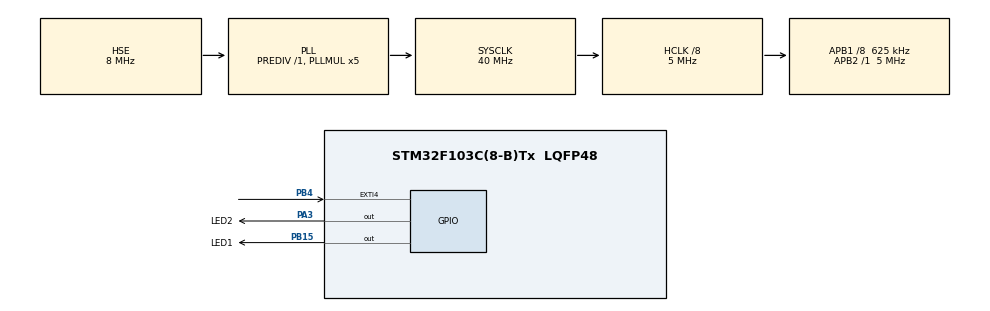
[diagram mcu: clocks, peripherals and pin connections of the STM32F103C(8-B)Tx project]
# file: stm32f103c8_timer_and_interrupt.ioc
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Mcu.Family=STM32F1
Mcu.Name=STM32F103C(8-B)Tx
Mcu.Package=LQFP48
NVIC.EXTI4_IRQn=true\:1\:0\:true\:false\:true\:true\:true\:true
NVIC.PriorityGroup=NVIC_PRIORITYGROUP_2
NVIC.TIM1_UP_IRQn=true\:2\:0\:true\:false\:true\:true\:true\:true
PA3.GPIO_Label=LED2
PA3.Signal=GPIO_Output
PB15.GPIO_Label=LED1
PB15.Signal=GPIO_Output
PB4.GPIO_ModeDefaultEXTI=GPIO_MODE_IT_FALLING
PB4.GPIO_PuPd=GPIO_PULLUP
PB4.Signal=GPXTI4
PD0-OSC_IN.Mode=HSE-External-Oscillator
PD0-OSC_IN.Signal=RCC_OSC_IN
PD1-OSC_OUT.Mode=HSE-External-Oscillator
PD1-OSC_OUT.Signal=RCC_OSC_OUT
ProjectManager.HeapSize=0x200
ProjectManager.StackSize=0x400
ProjectManager.TargetToolchain=STM32CubeIDE
RCC.AHBCLKDivider=RCC_SYSCLK_DIV8
RCC.AHBFreq_Value=5000000
RCC.APB1CLKDivider=RCC_HCLK_DIV8
RCC.APB1Freq_Value=625000
RCC.APB1TimFreq_Value=1250000
RCC.APB2Freq_Value=5000000
RCC.APB2TimFreq_Value=5000000
RCC.HCLKFreq_Value=5000000
RCC.PLLMUL=RCC_PLL_MUL5
RCC.PLLSourceVirtual=RCC_PLLSOURCE_HSE
RCC.SYSCLKFreq_VALUE=40000000
RCC.SYSCLKSource=RCC_SYSCLKSOURCE_PLLCLK
RCC.TimSys_Div=SYSTICK_CLKSOURCE_HCLK_DIV8
RCC.USBFreq_Value=40000000
TIM1.Period=5000
TIM1.RepetitionCounter=0
VP_SYS_VS_ND.Mode=No_Debug
VP_TIM1_VS_ClockSourceINT.Mode=Internal
board=custom

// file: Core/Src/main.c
/* USER CODE BEGIN Header */
/**
  ******************************************************************************
  * @file           : main.c
  * @brief          : Main program body
  ******************************************************************************
  * @attention
  *
  * Copyright (c) 2023 STMicroelectronics.
  * All rights reserved.
  *
  * This software is licensed under terms that can be found in the LICENSE file
  * in the root directory of this software component.
  * If no LICENSE file comes with this software, it is provided AS-IS.
  *
  ******************************************************************************
  */
/* USER CODE END Header */
#include "main.h"

TIM_HandleTypeDef htim1;

void SystemClock_Config(void);
static void MX_GPIO_Init(void);
static void MX_TIM1_Init(void);

/* USER CODE BEGIN 0 */

uint8_t	state_on_counter=0;
uint8_t	state_on=0;
uint8_t	state=1;
uint16_t miliseconds_count=0;
uint16_t miliseconds_int=0;
volatile uint8_t	change_flag=0;

/* USER CODE END 0 */

int main(void)
{

  /* MCU Configuration--------------------------------------------------------*/

  /* Reset of all peripherals, Initializes the Flash interface and the Systick. */
  HAL_Init();

  /* Configure the system clock */
  SystemClock_Config();

  /* Initialize all configured peripherals */
  MX_GPIO_Init();
  MX_TIM1_Init();
  /* USER CODE BEGIN 2 */
  HAL_TIM_Base_Start_IT(&htim1);
  /* USER CODE END 2 */

  /* Infinite loop */
  while (1)
  {

    /* USER CODE BEGIN 3 */

	  	switch(state){
	  		case 1:
	  	      miliseconds_count=0;
	  		  HAL_GPIO_WritePin(LED1_GPIO_Port, LED1_Pin,GPIO_PIN_SET);
	  		  HAL_GPIO_WritePin(LED2_GPIO_Port, LED2_Pin,GPIO_PIN_RESET);
	  		  while(miliseconds_count<50){
	  			if(change_flag){
	  				  				  				  break;
	  				  				  			  }
	  		  }
	  		  HAL_GPIO_TogglePin(LED1_GPIO_Port, LED1_Pin);
	  		  HAL_GPIO_TogglePin(LED2_GPIO_Port, LED2_Pin);
	  		  while(miliseconds_count<100){
	  			if(change_flag){
	  				change_flag=0;
	  				  				  				  break;
	  				  				  			  }
	  		  }
	  		break;

	  		case 2:

	  			 miliseconds_count=0;
	  				  		  HAL_GPIO_WritePin(LED1_GPIO_Port, LED1_Pin,GPIO_PIN_RESET);
	  				  		  HAL_GPIO_WritePin(LED2_GPIO_Port, LED2_Pin,GPIO_PIN_SET);
	  				  		  while(miliseconds_count<100){
	  				  			if(change_flag){
	  				  				  				  				  break;
	  				  				  				  			  }
	  				  		  }
	  				  		  HAL_GPIO_TogglePin(LED1_GPIO_Port, LED1_Pin);
	  				  		  HAL_GPIO_TogglePin(LED2_GPIO_Port, LED2_Pin);
	  				  		  while(miliseconds_count<200){
	  				  			if(change_flag){
	  				  			change_flag=0;
	  				  				  				  				  break;
	  				  				  				  			  }
	  				  		  }
	  	    break;

	  		case 3:

	  			 miliseconds_count=0;
	  				  		  HAL_GPIO_WritePin(LED1_GPIO_Port, LED1_Pin,GPIO_PIN_RESET);
	  				  		  HAL_GPIO_WritePin(LED2_GPIO_Port, LED2_Pin,GPIO_PIN_RESET);
	  				  		while(miliseconds_count<500){
	  				  			  if(change_flag){
	  				  				  break;
	  				  			  }
	  				  		  }
	  				  		  HAL_GPIO_TogglePin(LED1_GPIO_Port, LED1_Pin);
	  				  		  HAL_GPIO_TogglePin(LED2_GPIO_Port, LED2_Pin);
	  				  		while(miliseconds_count<1000){
	  				  		 if(change_flag){
	  				  			change_flag=0;
	  				  					 break;
	  				  			  	}
	  				  		  }

	  		break;

	  		case 4:
	  			HAL_GPIO_WritePin(LED1_GPIO_Port, LED1_Pin,GPIO_PIN_SET);
	  			HAL_GPIO_WritePin(LED2_GPIO_Port, LED2_Pin,GPIO_PIN_SET);

	  		break;

	  	}

  }
  /* USER CODE END 3 */
}

void SystemClock_Config(void)
{
  RCC_OscInitTypeDef RCC_OscInitStruct = {0};
  RCC_ClkInitTypeDef RCC_ClkInitStruct = {0};

  /** Initializes the RCC Oscillators according to the specified parameters
  * in the RCC_OscInitTypeDef structure.
  */
  RCC_OscInitStruct.OscillatorType = RCC_OSCILLATORTYPE_HSE;
  RCC_OscInitStruct.HSEState = RCC_HSE_ON;
  RCC_OscInitStruct.HSEPredivValue = RCC_HSE_PREDIV_DIV1;
  RCC_OscInitStruct.HSIState = RCC_HSI_ON;
  RCC_OscInitStruct.PLL.PLLState = RCC_PLL_ON;
  RCC_OscInitStruct.PLL.PLLSource = RCC_PLLSOURCE_HSE;
  RCC_OscInitStruct.PLL.PLLMUL = RCC_PLL_MUL5;
  if (HAL_RCC_OscConfig(&RCC_OscInitStruct) != HAL_OK)
  {
    Error_Handler();
  }

  /** Initializes the CPU, AHB and APB buses clocks
  */
  RCC_ClkInitStruct.ClockType = RCC_CLOCKTYPE_HCLK|RCC_CLOCKTYPE_SYSCLK
                              |RCC_CLOCKTYPE_PCLK1|RCC_CLOCKTYPE_PCLK2;
  RCC_ClkInitStruct.SYSCLKSource = RCC_SYSCLKSOURCE_PLLCLK;
  RCC_ClkInitStruct.AHBCLKDivider = RCC_SYSCLK_DIV8;
  RCC_ClkInitStruct.APB1CLKDivider = RCC_HCLK_DIV8;
  RCC_ClkInitStruct.APB2CLKDivider = RCC_HCLK_DIV1;

  if (HAL_RCC_ClockConfig(&RCC_ClkInitStruct, FLASH_LATENCY_1) != HAL_OK)
  {
    Error_Handler();
  }
}

static void MX_TIM1_Init(void)
{

  TIM_ClockConfigTypeDef sClockSourceConfig = {0};
  TIM_MasterConfigTypeDef sMasterConfig = {0};

  htim1.Instance = TIM1;
  htim1.Init.Prescaler = 0;
  htim1.Init.CounterMode = TIM_COUNTERMODE_UP;
  htim1.Init.Period = 5000;
  htim1.Init.ClockDivision = TIM_CLOCKDIVISION_DIV1;
  htim1.Init.RepetitionCounter = 0;
  htim1.Init.AutoReloadPreload = TIM_AUTORELOAD_PRELOAD_DISABLE;
  if (HAL_TIM_Base_Init(&htim1) != HAL_OK)
  {
    Error_Handler();
  }
  sClockSourceConfig.ClockSource = TIM_CLOCKSOURCE_INTERNAL;
  if (HAL_TIM_ConfigClockSource(&htim1, &sClockSourceConfig) != HAL_OK)
  {
    Error_Handler();
  }
  sMasterConfig.MasterOutputTrigger = TIM_TRGO_RESET;
  sMasterConfig.MasterSlaveMode = TIM_MASTERSLAVEMODE_DISABLE;
  if (HAL_TIMEx_MasterConfigSynchronization(&htim1, &sMasterConfig) != HAL_OK)
  {
    Error_Handler();
  }

}

static void MX_GPIO_Init(void)
{
  GPIO_InitTypeDef GPIO_InitStruct = {0};

  /* GPIO Ports Clock Enable */
  __HAL_RCC_GPIOD_CLK_ENABLE();
  __HAL_RCC_GPIOA_CLK_ENABLE();
  __HAL_RCC_GPIOB_CLK_ENABLE();

  /*Configure GPIO pin Output Level */
  HAL_GPIO_WritePin(LED2_GPIO_Port, LED2_Pin, GPIO_PIN_RESET);

  /*Configure GPIO pin Output Level */
  HAL_GPIO_WritePin(LED1_GPIO_Port, LED1_Pin, GPIO_PIN_RESET);

  /*Configure GPIO pin : LED2_Pin */
  GPIO_InitStruct.Pin = LED2_Pin;
  GPIO_InitStruct.Mode = GPIO_MODE_OUTPUT_PP;
  GPIO_InitStruct.Pull = GPIO_NOPULL;
  GPIO_InitStruct.Speed = GPIO_SPEED_FREQ_LOW;
  HAL_GPIO_Init(LED2_GPIO_Port, &GPIO_InitStruct);

  /*Configure GPIO pin : LED1_Pin */
  GPIO_InitStruct.Pin = LED1_Pin;
  GPIO_InitStruct.Mode = GPIO_MODE_OUTPUT_PP;
  GPIO_InitStruct.Pull = GPIO_NOPULL;
  GPIO_InitStruct.Speed = GPIO_SPEED_FREQ_LOW;
  HAL_GPIO_Init(LED1_GPIO_Port, &GPIO_InitStruct);

  /*Configure GPIO pin : PB4 */
  GPIO_InitStruct.Pin = GPIO_PIN_4;
  GPIO_InitStruct.Mode = GPIO_MODE_IT_FALLING;
  GPIO_InitStruct.Pull = GPIO_PULLUP;
  HAL_GPIO_Init(GPIOB, &GPIO_InitStruct);

  /* EXTI interrupt init*/
  HAL_NVIC_SetPriority(EXTI4_IRQn, 1, 0);
  HAL_NVIC_EnableIRQ(EXTI4_IRQn);

}

/* USER CODE BEGIN 4 */
void HAL_GPIO_EXTI_Callback(uint16_t GPIO_Pin)
{

	if(miliseconds_int>500){
		change_flag=1;
		miliseconds_int=0;
		state++;
					if(state>=5){
						state=1;
					}
	}

}

void HAL_TIM_PeriodElapsedCallback(TIM_HandleTypeDef* htim)
{
	 miliseconds_count++;
	 miliseconds_int++;

}
/* USER CODE END 4 */

void Error_Handler(void)
{
  __disable_irq();
  while (1)
  {
  }
}
